# APM32F103x8 register map
File version: 1.0
CPU: CM3 r2p1, little endian, no MPU, no FPU, 4 interrupt priority bits
Registers are 32-bit, read-write, reset 0x0 unless marked. A register's access mark holds for its fields unless they carry their own. Offsets are from the block's base; [hi:lo] are bit positions; {n}, {i} and the like mark numbered series.

## SPI1 — Serial peripheral interface
Base 0x40013000
Same registers: SPI2 0x40003800
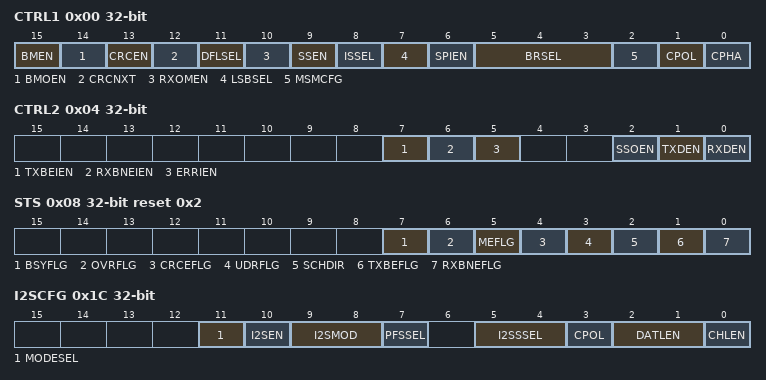
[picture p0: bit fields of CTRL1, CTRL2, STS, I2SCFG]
0x00 CTRL1 — control register 1
  [15] BMEN — Bidirectional data mode enable
  [14] BMOEN — Output enable in bidirectional mode
  [13] CRCEN — Hardware CRC calculation enable
  [12] CRCNXT — CRC transfer next
  [11] DFLSEL — Data frame format
  [10] RXOMEN — Receive only
  [9] SSEN — Software slave management
  [8] ISSEL — Internal slave select
  [7] LSBSEL — Frame format
  [6] SPIEN — SPI enable
  [5:3] BRSEL — Baud rate control
  [2] MSMCFG — Master selection
  [1] CPOL — Clock polarity
  [0] CPHA — Clock phase
0x04 CTRL2 — control register 2
  [7] TXBEIEN — Tx buffer empty interrupt enable
  [6] RXBNEIEN — RX buffer not empty interrupt enable
  [5] ERRIEN — Error interrupt enable
  [2] SSOEN — SS output enable
  [1] TXDEN — Tx buffer DMA enable
  [0] RXDEN — Rx buffer DMA enable
0x08 STS access per field reset 0x2 — status register
  [7] BSYFLG ro — Busy flag
  [6] OVRFLG ro — Overrun flag
  [5] MEFLG ro — Mode fault
  [4] CRCEFLG rw — CRC error flag
  [3] UDRFLG ro — Underrun flag
  [2] SCHDIR ro — Channel side
  [1] TXBEFLG ro — Transmit buffer empty
  [0] RXBNEFLG ro — Receive buffer not empty
0x0C DATA
  [15:0] DATA
0x10 CRCPOLY reset 0x7 — CRC polynomial register
  [15:0] CRCPOLY
0x14 RXCRC ro
  [15:0] RXCRC
0x18 TXCRC ro
  [15:0] TXCRC
0x1C I2SCFG — I2S configuration register
  [11] MODESEL — I2S mode selection
  [10] I2SEN — I2S Enable
  [9:8] I2SMOD — I2S configuration mode
  [7] PFSSEL — PCM frame synchronization
  [5:4] I2SSSEL — I2S standard selection
  [3] CPOL — Steady state clock polarity
  [2:1] DATLEN — Data length to be transferred
  [0] CHLEN — Channel length (number of bits per audio channel)
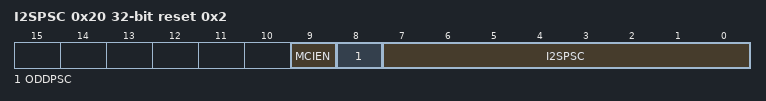
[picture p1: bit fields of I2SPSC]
0x20 I2SPSC reset 0x2 — I2S prescaler register
  [9] MCIEN — Master clock output enable
  [8] ODDPSC — Odd factor for the prescaler
  [7:0] I2SPSC — I2S Linear prescaler

## NVIC — Nested Vectored Interrupt Controller
Base 0xE000E000
0x04 ICTR ro — Interrupt Controller Type Register
  [3:0] INTLINESNUM — Total number of interrupt lines in groups
0x100 ISER0 — Interrupt Set-Enable Register
  [31:0] SETENA
0x104 ISER1 — Interrupt Set-Enable Register
  [31:0] SETENA
0x180 ICER0 — Interrupt Clear-Enable Register
  [31:0] CLRENA
0x184 ICER1 — Interrupt Clear-Enable Register
  [31:0] CLRENA
0x200 ISPR0 — Interrupt Set-Pending Register
  [31:0] SETPEND
0x204 ISPR1 — Interrupt Set-Pending Register
  [31:0] SETPEND
0x280 ICPR0 — Interrupt Clear-Pending Register
  [31:0] CLRPEND
0x284 ICPR1 — Interrupt Clear-Pending Register
  [31:0] CLRPEND
0x300 IABR0 ro — Interrupt Active Bit Register
  [31:0] ACTIVE
0x304 IABR1 ro — Interrupt Active Bit Register
  [31:0] ACTIVE
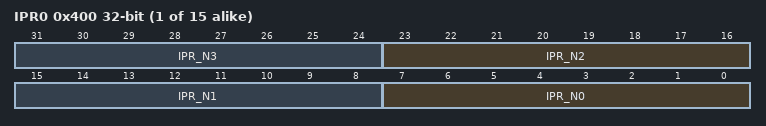
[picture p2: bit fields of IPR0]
{0x400+4i} IPR{i} (i=0..14) — Interrupt Priority Register
  [8n+7:8n] IPR_N{n} (n=0..3)
0xF00 STIR wo — Software Triggered Interrupt Register
  [8:0] INTID — interrupt to be triggered

## DBGMCU — Debug support
Base 0xE0042000
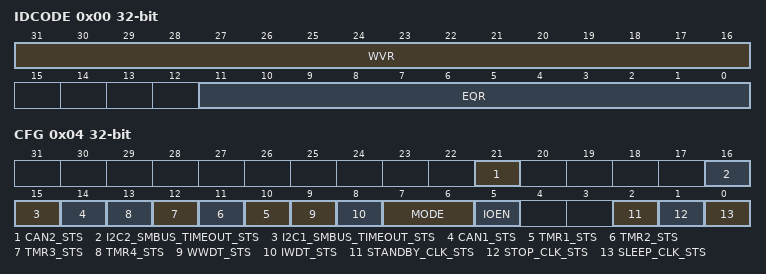
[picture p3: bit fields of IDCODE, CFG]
0x00 IDCODE ro — DBGMCU_IDCODE
  [31:16] WVR — Wafer Version Recognition
  [11:0] EQR — Equipment Recognition
0x04 CFG — DBGMCU_CFG
  [21] CAN2_STS, [16] I2C2_SMBUS_TIMEOUT_STS, [15] I2C1_SMBUS_TIMEOUT_STS, [14] CAN1_STS, [n+9] TMR{n}_STS (n=1..4), [9] WWDT_STS, [8] IWDT_STS, [7:6] MODE, [5] IOEN, [2] STANDBY_CLK_STS, [1] STOP_CLK_STS, [0] SLEEP_CLK_STS

## QSPI — Serial peripheral interface
Base 0xA0000000
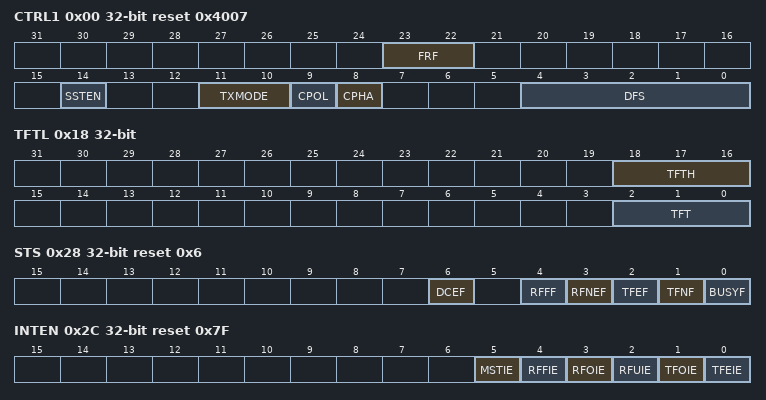
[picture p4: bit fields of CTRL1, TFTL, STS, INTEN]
0x00 CTRL1 reset 0x4007 — Control register 1
  [23:22] FRF, [14] SSTEN, [11:10] TXMODE, [9] CPOL, [8] CPHA, [4:0] DFS
0x04 CTRL2 — Control register 2
  [15:0] NDF
0x08 SSIEN — QSPI Enable register
  [0] EN
0x10 SLAEN — QSPI Slave enable register
  [0] SLAEN
0x14 BR — Baudrate register
  [15:0] CLKDIV
0x18 TFTL — Transmission FIFO threshhold level register
  [18:16] TFTH, [2:0] TFT
0x1C RFTL — Reception FIFO threshhold level register
  [2:0] RFT
0x20 TFL — Transmission FIFO level register
  [2:0] TFL
0x24 RFL — Reception FIFO level register
  [2:0] RFL
0x28 STS reset 0x6 — Status register
  [6] DCEF, [4] RFFF, [3] RFNEF, [2] TFEF, [1] TFNF, [0] BUSYF
0x2C INTEN reset 0x7F — Interrupt enable register
  [5] MSTIE, [4] RFFIE, [3] RFOIE, [2] RFUIE, [1] TFOIE, [0] TFEIE
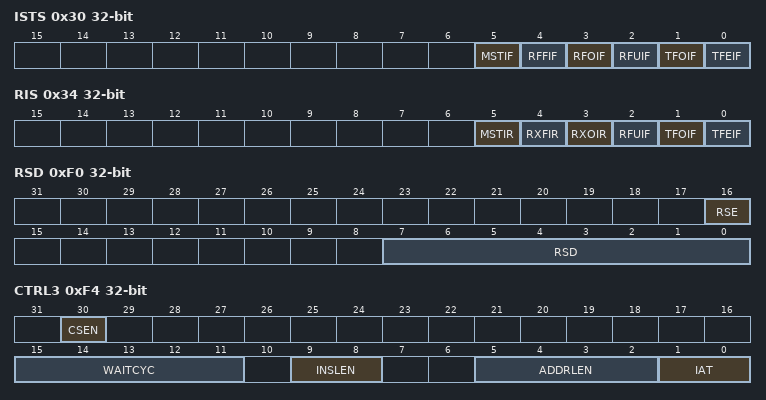
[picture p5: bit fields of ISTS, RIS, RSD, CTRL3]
0x30 ISTS ro — Interrupt status register
  [5] MSTIF, [4] RFFIF, [3] RFOIF, [2] RFUIF, [1] TFOIF, [0] TFEIF
0x34 RIS ro — Raw interrupt register
  [5] MSTIR, [4] RXFIR, [3] RXOIR, [2] RFUIF, [1] TFOIF, [0] TFEIF
0x38 TFOIC ro — Transmission FIFO overflow interrupt clear register
  [0] TFOIC
0x3C RFOIC ro — Reception FIFO overflow interrupt clear register
  [0] RFOIC
0x40 RFUIC ro — Reception FIFO underflow interrupt clear register
  [0] RFUIC
0x44 MIC ro — Master interrupt clear register
  [0] MIC
0x48 ICF ro — Interrupt clear register
  [0] ICF
0x60 DATA
0xF0 RSD — Reception sample register
  [16] RSE, [7:0] RSD
0xF4 CTRL3 — Control register 3
  [30] CSEN, [15:11] WAITCYC, [9:8] INSLEN, [5:2] ADDRLEN, [1:0] IAT
0x200 IOSW — IO switch register
  [0] IOSW — I/O switch

## USBD — Universal serial bus full-speed device interface
Base 0x40005C00
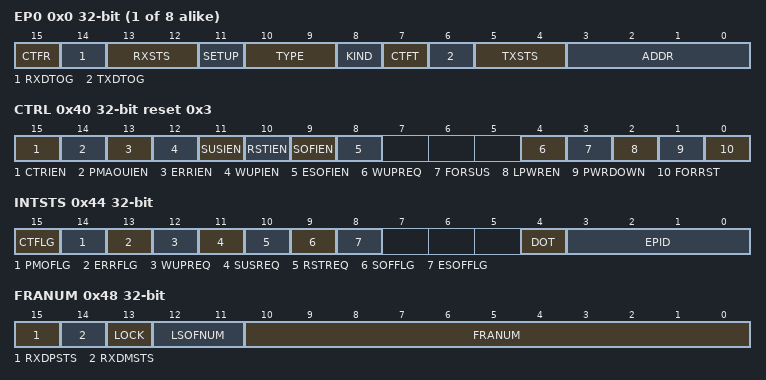
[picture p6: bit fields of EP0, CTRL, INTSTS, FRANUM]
{0x0+4i} EP{i} (i=0..7) — endpoint {i} register
  [15] CTFR — Correct transfer for reception
  [14] RXDTOG — Data Toggle, for reception transfers
  [13:12] RXSTS — Status bits, for reception transfers
  [11] SETUP — Setup transaction completed
  [10:9] TYPE — Endpoint type
  [8] KIND — Endpoint kind
  [7] CTFT — Correct Transfer for transmission
  [6] TXDTOG — Data Toggle, for transmission transfers
  [5:4] TXSTS — Status bits, for transmission transfers
  [3:0] ADDR — Endpoint address
0x40 CTRL reset 0x3 — control register
  [15] CTRIEN — Correct transfer interrupt mask
  [14] PMAOUIEN — Packet memory area over / underrun interrupt mask
  [13] ERRIEN — Error interrupt mask
  [12] WUPIEN — Wakeup interrupt mask
  [11] SUSIEN — Suspend mode interrupt mask
  [10] RSTIEN — USB reset interrupt mask
  [9] SOFIEN — Start of frame interrupt mask
  [8] ESOFIEN — Expected start of frame interrupt mask
  [4] WUPREQ — Wakeup request
  [3] FORSUS — Force suspend
  [2] LPWREN — Low-power mode
  [1] PWRDOWN — Power down
  [0] FORRST — Force USB Reset
0x44 INTSTS — interrupt status register
  [15] CTFLG — Correct transfer
  [14] PMOFLG — Packet memory area over / underrun
  [13] ERRFLG — Error
  [12] WUPREQ — Wakeup
  [11] SUSREQ — Suspend mode request
  [10] RSTREQ — reset request
  [9] SOFFLG — start of frame
  [8] ESOFFLG — Expected start frame
  [4] DOT — Direction of transaction
  [3:0] EPID — Endpoint Identifier
0x48 FRANUM ro — frame number register
  [15] RXDPSTS — Receive data + line status
  [14] RXDMSTS — Receive data - line status
  [13] LOCK — Locked
  [12:11] LSOFNUM — Lost SOF
  [10:0] FRANUM — Frame number
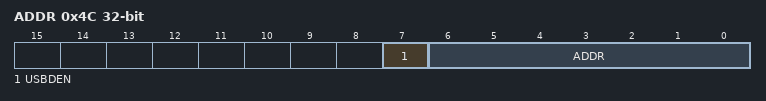
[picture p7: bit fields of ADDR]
0x4C ADDR — device address
  [7] USBDEN — Enable function
  [6:0] ADDR — Device address
0x50 BUFFTB — Buffer table address
  [15:3] BUFFTB — Buffer table
0x100 SWITCH
  [0] SWITCH
